# STM32G0C1 register map
File version: 1.8
CPU: CM0 r0p1, little endian, MPU, no FPU, 2 interrupt priority bits
Registers are 32-bit, read-write, reset 0x0 unless marked. A register's access mark holds for its fields unless they carry their own. Offsets are from the block's base; [hi:lo] are bit positions.

## COMP — Comparator
Base 0x40010200
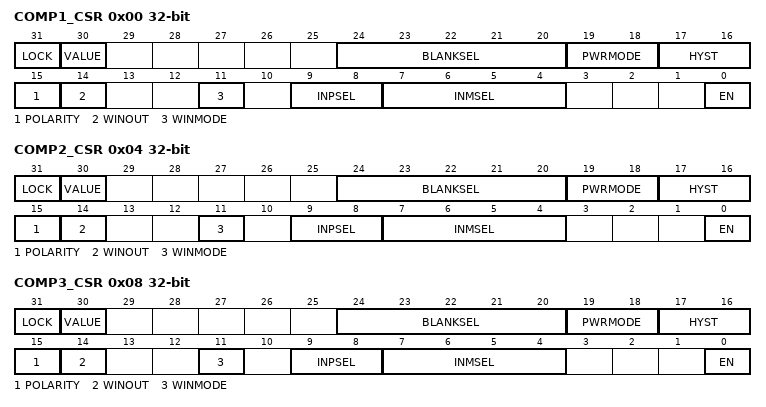
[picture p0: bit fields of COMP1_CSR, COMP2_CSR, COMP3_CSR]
0x00 COMP1_CSR access per field — Comparator 1 control and status register
  [31] LOCK rw — COMP1_CSR register lock This bit is set by software and cleared by a system reset. It locks the whole content of the comparator 1 control register COMP1_CSR[31:0]:
  [30] VALUE ro — Comparator 1 output status This bit is read-only. It reflects the level of the comparator 1 output after the polarity selector and blanking, as indicated in .
  [24:20] BLANKSEL rw — Comparator 1 blanking source selector This bitfield is controlled by software (if not locked). It selects the blanking source: xxxx1: TIM1 OC4 xxx1x: TIM1 OC5 xx1xx: TIM2 OC3 x1xxx: TIM3 OC3 1xxxx: TIM15 OC2
  [19:18] PWRMODE rw — Comparator 1 power mode selector This bitfield is controlled by software (if not locked). It selects the power consumption and as a consequence the speed of the comparator 1: others: Reserved
  [17:16] HYST rw — Comparator 1 hysteresis selector This bitfield is controlled by software (if not locked). It selects the hysteresis of the comparator 1:
  [15] POLARITY rw — Comparator 1 polarity selector This bit is controlled by software (if not locked). It selects the comparator 1 output polarity:
  [14] WINOUT rw — Comparator 1 output selector This bit is controlled by software (if not locked). It selects the comparator 1 output:
  [11] WINMODE rw — Comparator 1 non-inverting input selector for window mode This bit is controlled by software (if not locked). It selects the signal for COMP1_INP input of the comparator 1:
  [9:8] INPSEL rw — Comparator 1 signal selector for non-inverting input This bitfield is controlled by software (if not locked). It selects the signal for the non-inverting input COMP1_INP of the comparator 1 (also see the WINMODE bit):
  [7:4] INMSEL rw — Comparator 1 signal selector for inverting input INM This bitfield is controlled by software (if not locked). It selects the signal for the inverting input COMP1_INM of the comparator 1: > 1000: 1/4 VREFINT
  [0] EN rw — Comparator 1 enable bit This bit is controlled by software (if not locked). It enables the comparator 1:
0x04 COMP2_CSR access per field — Comparator 2 control and status register
  [31] LOCK rw — COMP2_CSR register lock This bit is set by software and cleared by a system reset. It locks the whole content of the comparator 2 control register COMP2_CSR[31:0]:
  [30] VALUE ro — Comparator 2 output status This bit is read-only. It reflects the level of the comparator 2 output after the polarity selector and blanking, as indicated in .
  [24:20] BLANKSEL rw — Comparator 2 blanking source selector This bitfield is controlled by software (if not locked). It selects the blanking source: xxxx1: TIM1 OC4 xxx1x: TIM1 OC5 xx1xx: TIM2 OC3 x1xxx: TIM3 OC3 1xxxx: TIM15 OC2
  [19:18] PWRMODE rw — Comparator 2 power mode selector This bitfield is controlled by software (if not locked). It selects the power consumption and as a consequence the speed of the comparator 2: others: Reserved
  [17:16] HYST rw — Comparator 2 hysteresis selector This bitfield is controlled by software (if not locked). It selects the hysteresis of the comparator 2:
  [15] POLARITY rw — Comparator 2 polarity selector This bit is controlled by software (if not locked). It selects the comparator 2 output polarity:
  [14] WINOUT rw — Comparator 2 output selector This bit is controlled by software (if not locked). It selects the comparator 2 output:
  [11] WINMODE rw — Comparator 2 non-inverting input selector for window mode This bit is controlled by software (if not locked). It selects the signal for COMP2_INP input of the comparator 2:
  [9:8] INPSEL rw — Comparator 2 signal selector for non-inverting input This bitfield is controlled by software (if not locked). It selects the signal for the non-inverting input COMP2_INP of the comparator 2 (also see the WINMODE bit):
  [7:4] INMSEL rw — Comparator 2 signal selector for inverting input INM This bitfield is controlled by software (if not locked). It selects the signal for the inverting input COMP2_INM of the comparator 2: > 1000: 1/4 VREFINT
  [0] EN rw — Comparator 2 enable bit This bit is controlled by software (if not locked). It enables the comparator 2:
0x08 COMP3_CSR access per field — Comparator 2 control and status register
  [31] LOCK rw — COMP3_CSR register lock This bit is set by software and cleared by a system reset. It locks the whole content of the comparator 3 control register COMP3_CSR[31:0]:
  [30] VALUE ro — Comparator 3 output status This bit is read-only. It reflects the level of the comparator 2 output after the polarity selector and blanking, as indicated in .
  [24:20] BLANKSEL rw — Comparator 3 blanking source selector This bitfield is controlled by software (if not locked). It selects the blanking source: xxxx1: TIM1 OC4 xxx1x: TIM1 OC5 xx1xx: TIM2 OC3 x1xxx: TIM3 OC3 1xxxx: TIM15 OC2
  [19:18] PWRMODE rw — Comparator 3 power mode selector This bitfield is controlled by software (if not locked). It selects the power consumption and as a consequence the speed of the comparator 3: others: Reserved
  [17:16] HYST rw — Comparator 3 hysteresis selector This bitfield is controlled by software (if not locked). It selects the hysteresis of the comparator 3:
  [15] POLARITY rw — Comparator 2 polarity selector This bit is controlled by software (if not locked). It selects the comparator 3 output polarity:
  [14] WINOUT rw — Comparator 3 output selector This bit is controlled by software (if not locked). It selects the comparator 3 output:
  [11] WINMODE rw — Comparator 3 non-inverting input selector for window mode This bit is controlled by software (if not locked). It selects the signal for COMP3_INP input of the comparator 3:
  [9:8] INPSEL rw — Comparator 3 signal selector for non-inverting input This bitfield is controlled by software (if not locked). It selects the signal for the non-inverting input COMP3_INP of the comparator 3 (also see the WINMODE bit):
  [7:4] INMSEL rw — Comparator 3 signal selector for inverting input INM This bitfield is controlled by software (if not locked). It selects the signal for the inverting input COMP3_INM of the comparator 3: > 1000: 1/4 VREFINT
  [0] EN rw — Comparator 3 enable bit This bit is controlled by software (if not locked). It enables the comparator 3:
